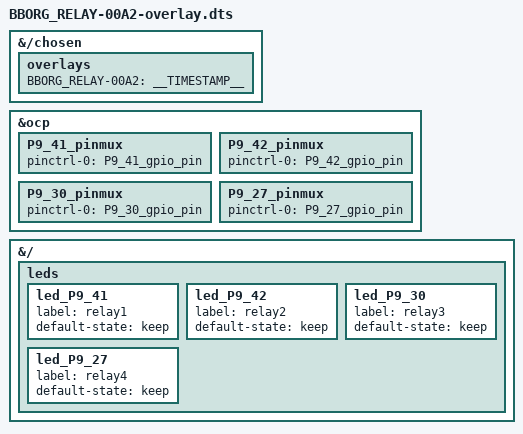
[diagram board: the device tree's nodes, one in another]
/*
 * Copyright (C) 2020 Deepak Khatri <deepaklorkhatri7@gmail.com>
 *
 * Based on the BBORG_RELAY-00A2.dts written by
 * Robert Nelson & Amilcar Lucas for kernel <4.14
 * Copyright (C) 2015 Robert Nelson <robertcnelson@gmail.com>
 * Copyright (C) 2019 Amilcar Lucas <amilcar.lucas@iav.de>
 *
 * This program is free software; you can redistribute it and/or modify
 * it under the terms of the GNU General Public License version 2 as
 * published by the Free Software Foundation.
 */

/dts-v1/;
/plugin/;

/*
 * Helper to show loaded overlays under: /proc/device-tree/chosen/overlays/
 */
&{/chosen} {
	overlays {
		BBORG_RELAY-00A2 = __TIMESTAMP__;
	};
};

/*
 * Free up the pins used by the cape from the pinmux helpers.
 */
&ocp {
	P9_41_pinmux { status = "disabled"; };
	P9_42_pinmux { status = "disabled"; };
	P9_30_pinmux { status = "disabled"; };
	P9_27_pinmux { status = "disabled"; };
};

/*
 * Enable and Update the default state of the pins
 */
&ocp {
	P9_41_pinmux { status = "okay"; pinctrl-0 = <&P9_41_gpio_pin>;};
	P9_42_pinmux { status = "okay"; pinctrl-0 = <&P9_42_gpio_pin>;};
	P9_30_pinmux { status = "okay"; pinctrl-0 = <&P9_30_gpio_pin>;};
	P9_27_pinmux { status = "okay"; pinctrl-0 = <&P9_27_gpio_pin>;};
};

/*
 * Easy relay control through sysfs (/sys/class/leds/) using gpio-leds driver
 * See these files for the led_P8_#/led_P9_#  definition
 * https://github.com/beagleboard/BeagleBoard-DeviceTrees/src/arm/bbai-bone-buses.dtsi
 * https://github.com/beagleboard/BeagleBoard-DeviceTrees/src/arm/bbb-bone-buses.dtsi
 *
 */
&{/} {
	leds {

		// relay1
		led_P9_41{
			status = "okay";
			label = "relay1";
			default-state = "keep";
		};

		// relay2
		led_P9_42{
			status = "okay";
			label = "relay2";
			default-state = "keep";
		};

		// realy3
		led_P9_30{
			status = "okay";
			label = "relay3";
			default-state = "keep";
		};

		// realy4
		led_P9_27{
			status = "okay";
			label = "relay4";
			default-state = "keep";
		};
	};
};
